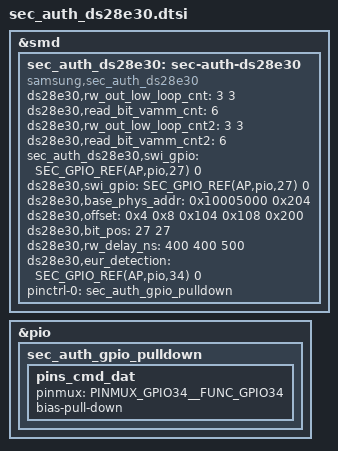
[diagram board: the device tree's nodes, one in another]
&smd {
	sec_auth_ds28e30: sec-auth-ds28e30 {
			status = "okay";
			compatible = "samsung,sec_auth_ds28e30";
			/* read bit out low loop count , write bit out low loop count for main battery*/
			ds28e30,rw_out_low_loop_cnt = <3 3>;
			ds28e30,read_bit_vamm_cnt = <6>;
			/* read bit out low loop count , write bit out low loop count for sub battery*/
			ds28e30,rw_out_low_loop_cnt2 = <3 3>;
			ds28e30,read_bit_vamm_cnt2 = <6>;
#if 1
			sec_auth_ds28e30,swi_gpio = <
				SEC_GPIO_REF(AP,pio,27) 0 /* SWI_GPIO */
#if 0
				SEC_GPIO_REF(${swi_gpio_2}) 0 /* SWI_GPIO_2 */
#endif
			>;
#endif
			};
};


/* /home/dpi/qb5_8814/workspace/P4_1716/android/kernel/kmodule/battery/suwon/battery_auth/ds28e30/a17/sec_auth_ds28e30.dtsi */
&pio {
	sec_auth_gpio_pulldown: sec_auth_gpio_pulldown {
		pins_cmd_dat {
			pinmux = <PINMUX_GPIO34__FUNC_GPIO34>;
			bias-pull-down;
		};
	};
};

&smd {
	sec_auth_ds28e30: sec-auth-ds28e30 {
		status = "okay";
		compatible = "samsung,sec_auth_ds28e30";

#if 1
		/* SWI_GPIO */
		ds28e30,swi_gpio = <SEC_GPIO_REF(AP,pio,27) 0 >;
		/* Change according to AP and GPIO */
		ds28e30,base_phys_addr = <0x10005000 0x204>;
		/* control_set , control_clr , data_set , data_clr , data_read */
		ds28e30,offset = <0x4 0x8 0x104 0x108 0x200>;
		/* Control bit is 27th , Data bit is 27th --> Change according to AP and GPIO */
		ds28e30,bit_pos = <27 27>;
		/* 400ns delay for tW1L , 400ns delay for tRL, 500ns delay for tSETUP */
		ds28e30,rw_delay_ns = <400 400 500>;
#endif
#if 1
		/*EUR_DETECTION_NODE*/
		ds28e30,eur_detection = <SEC_GPIO_REF(AP,pio,34) 0 >;
		pinctrl-names = "pulldown";
		pinctrl-0 = <&sec_auth_gpio_pulldown>;
#endif
	};
};
